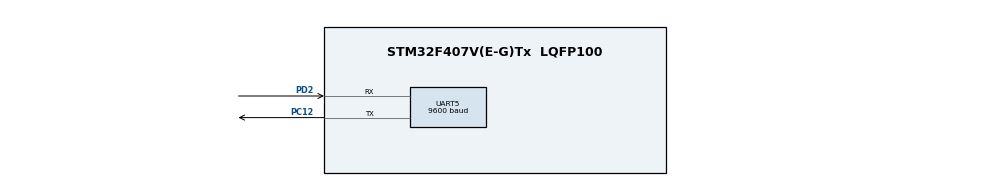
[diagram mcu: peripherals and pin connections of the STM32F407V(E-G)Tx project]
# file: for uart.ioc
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Dma.Request0=UART5_RX
Dma.Request1=UART5_TX
Dma.UART5_RX.0.Direction=DMA_PERIPH_TO_MEMORY
Dma.UART5_RX.0.FIFOMode=DMA_FIFOMODE_DISABLE
Dma.UART5_RX.0.Instance=DMA1_Stream0
Dma.UART5_RX.0.MemDataAlignment=DMA_MDATAALIGN_BYTE
Dma.UART5_RX.0.MemInc=DMA_MINC_ENABLE
Dma.UART5_RX.0.Mode=DMA_NORMAL
Dma.UART5_RX.0.PeriphDataAlignment=DMA_PDATAALIGN_BYTE
Dma.UART5_RX.0.PeriphInc=DMA_PINC_DISABLE
Dma.UART5_RX.0.Priority=DMA_PRIORITY_LOW
Dma.UART5_TX.1.Direction=DMA_MEMORY_TO_PERIPH
Dma.UART5_TX.1.FIFOMode=DMA_FIFOMODE_DISABLE
Dma.UART5_TX.1.Instance=DMA1_Stream7
Dma.UART5_TX.1.MemDataAlignment=DMA_MDATAALIGN_BYTE
Dma.UART5_TX.1.MemInc=DMA_MINC_ENABLE
Dma.UART5_TX.1.Mode=DMA_NORMAL
Dma.UART5_TX.1.PeriphDataAlignment=DMA_PDATAALIGN_BYTE
Dma.UART5_TX.1.PeriphInc=DMA_PINC_DISABLE
Dma.UART5_TX.1.Priority=DMA_PRIORITY_LOW
Mcu.Family=STM32F4
Mcu.Name=STM32F407V(E-G)Tx
Mcu.Package=LQFP100
NVIC.DMA1_Stream0_IRQn=true\:0\:0\:false\:false\:true\:false\:true\:true
NVIC.DMA1_Stream7_IRQn=true\:0\:0\:false\:false\:true\:false\:true\:true
NVIC.PriorityGroup=NVIC_PRIORITYGROUP_4
NVIC.UART5_IRQn=true\:0\:0\:false\:false\:true\:true\:true\:true
PC12.Mode=Asynchronous
PC12.Signal=UART5_TX
PD2.Mode=Asynchronous
PD2.Signal=UART5_RX
ProjectManager.HeapSize=0x200
ProjectManager.StackSize=0x400
ProjectManager.TargetToolchain=STM32CubeIDE
RCC.48MHZClocksFreq_Value=84000000
RCC.AHBFreq_Value=168000000
RCC.APB1CLKDivider=RCC_HCLK_DIV4
RCC.APB1Freq_Value=42000000
RCC.APB1TimFreq_Value=84000000
RCC.APB2CLKDivider=RCC_HCLK_DIV2
RCC.APB2Freq_Value=84000000
RCC.APB2TimFreq_Value=168000000
RCC.CortexFreq_Value=168000000
RCC.HCLKFreq_Value=168000000
RCC.HSE_VALUE=25000000
RCC.HSI_VALUE=16000000
RCC.LSE_VALUE=32768
RCC.PLLM=8
RCC.PLLN=168
RCC.SYSCLKFreq_VALUE=168000000
RCC.SYSCLKSource=RCC_SYSCLKSOURCE_PLLCLK
RCC.VCOOutputFreq_Value=336000000
UART5.BaudRate=9600
UART5.VirtualMode=Asynchronous
board=custom

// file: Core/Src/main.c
/* USER CODE BEGIN Header */
/**
  ******************************************************************************
  * @file           : main.c
  * @brief          : Main program body
  ******************************************************************************
  * @attention
  *
  * Copyright (c) 2023 STMicroelectronics.
  * All rights reserved.
  *
  * This software is licensed under terms that can be found in the LICENSE file
  * in the root directory of this software component.
  * If no LICENSE file comes with this software, it is provided AS-IS.
  *
  ******************************************************************************
  */
/* USER CODE END Header */
#include "main.h"
#include "dma.h"
#include "usart.h"
#include "gpio.h"

/* USER CODE BEGIN PV */
uint8_t rx_str[1];
uint8_t fl_rx=0, fl_tx=0;

uint8_t tx_str[12] = "bla bla bla\n";
/* USER CODE END PV */

void SystemClock_Config(void);

/* USER CODE BEGIN 0 */
void USART_TX (uint8_t* dt, uint16_t sz)
{
  LL_DMA_DisableStream(DMA1, LL_DMA_STREAM_7);
  LL_DMA_SetDataLength(DMA1, LL_DMA_STREAM_7, sz);
  LL_DMA_EnableStream(DMA1, LL_DMA_STREAM_7);
  while (!fl_tx) {}
  fl_tx=0;
}
//-------------------------------------------------------
void USART_RX (uint8_t* dt, uint16_t sz)
{
  LL_DMA_DisableStream(DMA1, LL_DMA_STREAM_0);
  LL_DMA_SetDataLength(DMA1, LL_DMA_STREAM_0, sz);
  LL_DMA_EnableStream(DMA1, LL_DMA_STREAM_0);
  while (!fl_rx) {}
  fl_rx=0;
}
/* USER CODE END 0 */

int main(void)
{

  /* MCU Configuration--------------------------------------------------------*/

  /* Reset of all peripherals, Initializes the Flash interface and the Systick. */
  LL_APB2_GRP1_EnableClock(LL_APB2_GRP1_PERIPH_SYSCFG);
  LL_APB1_GRP1_EnableClock(LL_APB1_GRP1_PERIPH_PWR);

  /* System interrupt init*/
  NVIC_SetPriorityGrouping(NVIC_PRIORITYGROUP_4);

  /* SysTick_IRQn interrupt configuration */
  NVIC_SetPriority(SysTick_IRQn, NVIC_EncodePriority(NVIC_GetPriorityGrouping(),15, 0));

  /* Configure the system clock */
  SystemClock_Config();

  /* Initialize all configured peripherals */
  MX_GPIO_Init();
  MX_DMA_Init();
  MX_UART5_Init();
  /* USER CODE BEGIN 2 */
  LL_DMA_DisableStream(DMA1, LL_DMA_STREAM_0);
  LL_DMA_DisableStream(DMA1, LL_DMA_STREAM_7);
  LL_DMA_ClearFlag_TC0(DMA1);
  LL_DMA_ClearFlag_TC7(DMA1);
  LL_DMA_ClearFlag_TE0(DMA1);
  LL_DMA_ClearFlag_TE7(DMA1);
  LL_USART_EnableDMAReq_TX(UART5);
  LL_USART_EnableDMAReq_RX(UART5);
  LL_DMA_EnableIT_TC(DMA1, LL_DMA_STREAM_0);
  LL_DMA_EnableIT_TE(DMA1, LL_DMA_STREAM_0);
  LL_DMA_EnableIT_TC(DMA1, LL_DMA_STREAM_7);
  LL_DMA_EnableIT_TE(DMA1, LL_DMA_STREAM_7);
  LL_DMA_ClearFlag_TC0(DMA1);
  LL_DMA_ClearFlag_TE0(DMA1);
  LL_DMA_ClearFlag_TC7(DMA1);
  LL_DMA_ClearFlag_TC7(DMA1);
  LL_DMA_ConfigAddresses(DMA1, LL_DMA_STREAM_0, LL_USART_DMA_GetRegAddr(UART5), (uint32_t)&rx_str, LL_DMA_GetDataTransferDirection(DMA1, LL_DMA_STREAM_0));
  LL_DMA_ConfigAddresses(DMA1, LL_DMA_STREAM_7, (uint32_t)&tx_str, LL_USART_DMA_GetRegAddr(UART5), LL_DMA_GetDataTransferDirection(DMA1, LL_DMA_STREAM_7));
  /* USER CODE END 2 */
  uint32_t f = GPIO_IDR_IDR_13;
  /* Infinite loop */
  /* USER CODE BEGIN WHILE */

  while (1)
  {
	  USART_RX(rx_str, 1);
	  USART_TX(tx_str,12);
    /* USER CODE END WHILE */

  }
}

void SystemClock_Config(void)
{
  LL_FLASH_SetLatency(LL_FLASH_LATENCY_5);
  while(LL_FLASH_GetLatency()!= LL_FLASH_LATENCY_5)
  {
  }
  LL_PWR_SetRegulVoltageScaling(LL_PWR_REGU_VOLTAGE_SCALE1);
  LL_RCC_HSI_SetCalibTrimming(16);
  LL_RCC_HSI_Enable();

   /* Wait till HSI is ready */
  while(LL_RCC_HSI_IsReady() != 1)
  {

  }
  LL_RCC_PLL_ConfigDomain_SYS(LL_RCC_PLLSOURCE_HSI, LL_RCC_PLLM_DIV_8, 168, LL_RCC_PLLP_DIV_2);
  LL_RCC_PLL_Enable();

   /* Wait till PLL is ready */
  while(LL_RCC_PLL_IsReady() != 1)
  {

  }
  LL_RCC_SetAHBPrescaler(LL_RCC_SYSCLK_DIV_1);
  LL_RCC_SetAPB1Prescaler(LL_RCC_APB1_DIV_4);
  LL_RCC_SetAPB2Prescaler(LL_RCC_APB2_DIV_2);
  LL_RCC_SetSysClkSource(LL_RCC_SYS_CLKSOURCE_PLL);

   /* Wait till System clock is ready */
  while(LL_RCC_GetSysClkSource() != LL_RCC_SYS_CLKSOURCE_STATUS_PLL)
  {

  }
  LL_Init1msTick(168000000);
  LL_SetSystemCoreClock(168000000);
}

/* USER CODE BEGIN 4 */
void DMA1_Stream0_TransferComplete(void)
{
  LL_DMA_ClearFlag_TC0(DMA1);
  fl_rx = 1;
}
//-----------------------------------------------
void DMA1_Stream7_TransferComplete(void)
{
  LL_DMA_ClearFlag_TC7(DMA1);
  fl_tx = 1;
}
/* USER CODE END 4 */

void Error_Handler(void)
{
  __disable_irq();
  while (1)
  {
  }
}
